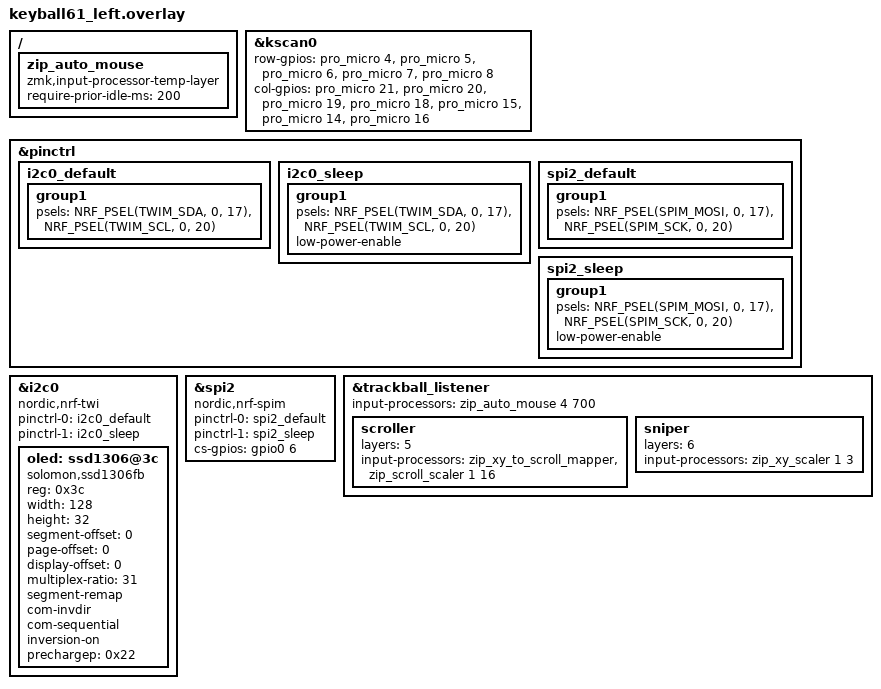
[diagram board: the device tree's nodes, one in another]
/*
 * Copyright (c) 2020 ZMK Contributors
 *
 * SPDX-License-Identifier: MIT
 */

#include "keyball61.dtsi"
#include <input/processors.dtsi>

&kscan0 {
	row-gpios
        = <&pro_micro 4 (GPIO_ACTIVE_HIGH | GPIO_PULL_DOWN)>
        , <&pro_micro 5 (GPIO_ACTIVE_HIGH | GPIO_PULL_DOWN)>
        , <&pro_micro 6 (GPIO_ACTIVE_HIGH | GPIO_PULL_DOWN)>
        , <&pro_micro 7 (GPIO_ACTIVE_HIGH | GPIO_PULL_DOWN)>
        , <&pro_micro 8 (GPIO_ACTIVE_HIGH | GPIO_PULL_DOWN)>
        ;
    col-gpios
        = <&pro_micro 21 GPIO_ACTIVE_HIGH>
        , <&pro_micro 20 GPIO_ACTIVE_HIGH>
        , <&pro_micro 19 GPIO_ACTIVE_HIGH>
	    , <&pro_micro 18 GPIO_ACTIVE_HIGH>
		, <&pro_micro 15 GPIO_ACTIVE_HIGH>
		, <&pro_micro 14 GPIO_ACTIVE_HIGH>
		, <&pro_micro 16 GPIO_ACTIVE_HIGH>
		;
};

&pinctrl {
    i2c0_default: i2c0_default {
        group1 {
            psels = <NRF_PSEL(TWIM_SDA, 0, 17)>,
                    <NRF_PSEL(TWIM_SCL, 0, 20)>;
        };
    };

    i2c0_sleep: i2c0_sleep {
        group1 {
            psels = <NRF_PSEL(TWIM_SDA, 0, 17)>,
                    <NRF_PSEL(TWIM_SCL, 0, 20)>;
            low-power-enable;
        };
    };
};

&i2c0 {
    status = "okay";
    compatible = "nordic,nrf-twi";
    pinctrl-0 = <&i2c0_default>;
    pinctrl-1 = <&i2c0_sleep>;
    pinctrl-names = "default", "sleep";

    oled: ssd1306@3c {
        compatible = "solomon,ssd1306fb";
        reg = <0x3c>;
        width = <128>;
        height = <32>;
        segment-offset = <0>;
        page-offset = <0>;
        display-offset = <0>;
        multiplex-ratio = <31>;
        segment-remap;
        com-invdir;
        com-sequential;
        inversion-on;
        prechargep = <0x22>;
    };
};

/*
 * Left half nice!view SPI.
 *
 * The display connector on this board is wired for SPI, but not on the pins
 * nice_view_adapter assumes, so spi2 is declared directly here:
 * MOSI P0.17, SCK P0.20, CS P0.06.
 *
 * Do not add nice_view_adapter to the shield list. This file and that shield both
 * label spi2 as nice_view_spi, and the build stops with
 *   "Label 'nice_view_spi' appears on ..."
 *
 * config/keyball61.keymap re-states the same CS as <&pro_micro 1>. On nice_nano_v2
 * pro_micro pin 1 is P0.06, so the two agree.
 */
&pinctrl {
    spi2_default: spi2_default {
        group1 {
            psels = <NRF_PSEL(SPIM_MOSI, 0, 17)>,
                    <NRF_PSEL(SPIM_SCK, 0, 20)>;
        };
    };

    spi2_sleep: spi2_sleep {
        group1 {
            psels = <NRF_PSEL(SPIM_MOSI, 0, 17)>,
                    <NRF_PSEL(SPIM_SCK, 0, 20)>;
            low-power-enable;
        };
    };
};

nice_view_spi: &spi2 {
    compatible = "nordic,nrf-spim";
    pinctrl-0 = <&spi2_default>;
    pinctrl-1 = <&spi2_sleep>;
    pinctrl-names = "default", "sleep";
    cs-gpios = <&gpio0 6 (GPIO_ACTIVE_HIGH | GPIO_PULL_DOWN)>;
};

/*
 * Everything the trackball does per layer, evaluated on the central half.
 *
 *   layer 4 MOUSE   moving the ball switches it in for 700 ms, but only if no key was
 *                   struck in the previous 200 ms. That idle guard is what stops a
 *                   palm brushing the ball mid-word from hijacking the cursor.
 *   layer 5 SCROLL  XY deltas become wheel events at 1/16 speed.
 *   layer 6 SNIPE   XY deltas scaled to 1/3.
 *
 * The indices match the declaration order in config/keyball61.keymap:
 * default=0 number=1 symbol=2 function=3 mouse=4 scroll=5 snipe=6. The #define block
 * at the top of that file (MOUSE 3 / SCROLL 4 / SNIPE 5) is stale and no binding uses
 * it, so trust the declaration order instead.
 */
/ {
    zip_auto_mouse: zip_auto_mouse {
        compatible = "zmk,input-processor-temp-layer";
        #input-processor-cells = <2>;
        require-prior-idle-ms = <200>;
    };
};

&trackball_listener {
    status = "okay";
    input-processors = <&zip_auto_mouse 4 700>;

    scroller {
        layers = <5>;
        input-processors = <&zip_xy_to_scroll_mapper>, <&zip_scroll_scaler 1 16>;
    };

    sniper {
        layers = <6>;
        input-processors = <&zip_xy_scaler 1 3>;
    };
};
